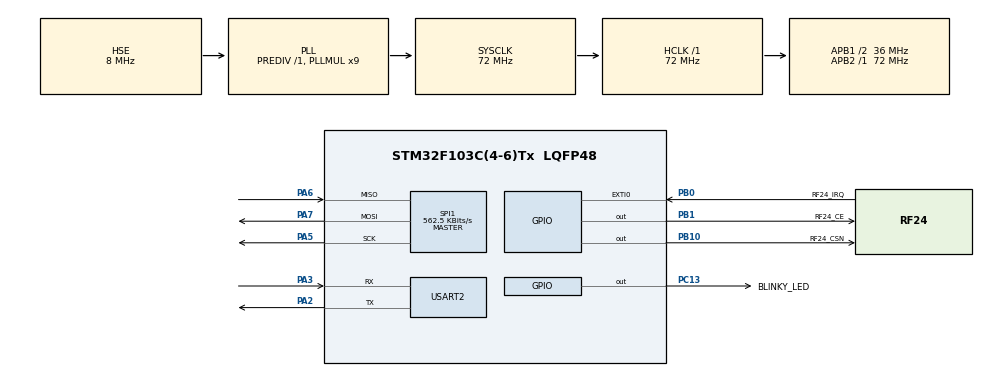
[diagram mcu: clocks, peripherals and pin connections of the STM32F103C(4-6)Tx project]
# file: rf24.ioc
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ADC1.Channel-0\#ChannelRegularConversion=ADC_CHANNEL_TEMPSENSOR
ADC1.NbrOfConversionFlag=1
ADC1.Rank-0\#ChannelRegularConversion=1
ADC1.SamplingTime-0\#ChannelRegularConversion=ADC_SAMPLETIME_1CYCLE_5
ADC1.master=1
Mcu.Family=STM32F1
Mcu.Name=STM32F103C(4-6)Tx
Mcu.Package=LQFP48
NVIC.PriorityGroup=NVIC_PRIORITYGROUP_4
PA2.Mode=Asynchronous
PA2.Signal=USART2_TX
PA3.Mode=Asynchronous
PA3.Signal=USART2_RX
PA5.Mode=Full_Duplex_Master
PA5.Signal=SPI1_SCK
PA6.Mode=Full_Duplex_Master
PA6.Signal=SPI1_MISO
PA7.Mode=Full_Duplex_Master
PA7.Signal=SPI1_MOSI
PB0.GPIO_Label=RF24_IRQ
PB0.GPIO_PuPd=GPIO_PULLUP
PB0.Signal=GPXTI0
PB1.GPIO_Label=RF24_CE
PB1.GPIO_PuPd=GPIO_PULLUP
PB1.GPIO_Speed=GPIO_SPEED_FREQ_HIGH
PB1.Signal=GPIO_Output
PB10.GPIO_Label=RF24_CSN
PB10.GPIO_PuPd=GPIO_PULLUP
PB10.GPIO_Speed=GPIO_SPEED_FREQ_HIGH
PB10.PinState=GPIO_PIN_RESET
PB10.Signal=GPIO_Output
PC13-TAMPER-RTC.GPIO_Label=BLINKY_LED
PC13-TAMPER-RTC.Signal=GPIO_Output
PD0-OSC_IN.Mode=HSE-External-Oscillator
PD0-OSC_IN.Signal=RCC_OSC_IN
PD1-OSC_OUT.Mode=HSE-External-Oscillator
PD1-OSC_OUT.Signal=RCC_OSC_OUT
ProjectManager.HeapSize=0x300
ProjectManager.StackSize=0x300
ProjectManager.TargetToolchain=SW4STM32
RCC.ADCPresc=RCC_ADCPCLK2_DIV6
RCC.AHBFreq_Value=72000000
RCC.APB1CLKDivider=RCC_HCLK_DIV2
RCC.APB1Freq_Value=36000000
RCC.APB1TimFreq_Value=72000000
RCC.APB2Freq_Value=72000000
RCC.APB2TimFreq_Value=72000000
RCC.HCLKFreq_Value=72000000
RCC.PLLMUL=RCC_PLL_MUL9
RCC.PLLSourceVirtual=RCC_PLLSOURCE_HSE
RCC.SYSCLKFreq_VALUE=72000000
RCC.SYSCLKSource=RCC_SYSCLKSOURCE_PLLCLK
RCC.USBFreq_Value=48000000
RCC.USBPrescaler=RCC_USBCLKSOURCE_PLL_DIV1_5
SPI1.BaudRatePrescaler=SPI_BAUDRATEPRESCALER_128
SPI1.CLKPolarity=SPI_POLARITY_LOW
SPI1.CalculateBaudRate=562.5 KBits/s
SPI1.DataSize=SPI_DATASIZE_8BIT
SPI1.Direction=SPI_DIRECTION_2LINES
SPI1.FirstBit=SPI_FIRSTBIT_MSB
SPI1.Mode=SPI_MODE_MASTER
SPI1.VirtualType=VM_MASTER
TIM1.AutoReloadPreload=TIM_AUTORELOAD_PRELOAD_ENABLE
TIM1.Period=18000
TIM1.Prescaler=65535
USART2.VirtualMode=VM_ASYNC
VP_ADC1_TempSens_Input.Mode=IN-TempSens
VP_SYS_VS_ND.Mode=No_Debug
VP_TIM1_VS_ClockSourceINT.Mode=Internal
VP_TIM1_VS_OPM.Mode=OPM_bit
board=custom

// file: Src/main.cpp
/* USER CODE BEGIN Header */
/**
 ******************************************************************************
 * @file           : main.c
 * @brief          : Main program body
 ******************************************************************************
 * @attention
 *
 * <h2><center>&copy; Copyright (c) 2020 STMicroelectronics.
 * All rights reserved.</center></h2>
 *
 * This software component is licensed by ST under BSD 3-Clause license,
 * the "License"; You may not use this file except in compliance with the
 * License. You may obtain a copy of the License at:
 *                        opensource.org/licenses/BSD-3-Clause
 *
 ******************************************************************************
 */
/* USER CODE END Header */

#include "main.h"

#include "DataTypes.h"
//#include "RF24.h"
#include "Nrf24.h"
#include "STM32Syscalls.h"
#include "Mesh.h"
#include "DebugSingleton.h"
#include "STM32Debug.h"
//#include <stdlib.h>

SPI_HandleTypeDef hspi1;
TIM_HandleTypeDef htim1;
UART_HandleTypeDef huart2;
ADC_HandleTypeDef hadc1;

void SystemClock_Config(void);
static void MX_GPIO_Init(void);
static void MX_SPI1_Init(void);
static void MX_TIM1_Init(void);
static void MX_USART2_UART_Init(void);
static void MX_ADC1_Init(void);

/* USER CODE BEGIN PFP */
/* USER CODE BEGIN PFP */

/* USER CODE END PFP */

//gpio::GPIOInterface *mesh_gpio;
syscalls::SyscallsInterface *mesh_syscalls;
//spi::SPIInterface *mesh_spi;
//network::RF24 *radio;
debugger::DebugInterface *debug;
mesh::Mesh *meshNetwork;
network::NetworkInterface *nwInterface;

bool server = false;

/****************** User Config ***************************/
/***      Set this radio as radio number 0 or 1         ***/
bool radioNumber = 0;

/* Hardware configuration: Set up nRF24L01 radio on SPI bus plus pins 7 & 8 */
/**********************************************************/

uint8_t addresses[][6] = {"1Node","2Node"};

// Used to control whether this node is sending or receiving
bool role = radioNumber;

int main(void)
{

	/* MCU Configuration--------------------------------------------------------*/

	/* Reset of all peripherals, Initializes the Flash interface and the Systick. */
	HAL_Init();

	/* Configure the system clock */
	SystemClock_Config();

	/* Initialize all configured peripherals */
	MX_GPIO_Init();
	MX_SPI1_Init();
	MX_TIM1_Init();
	MX_USART2_UART_Init();
	MX_ADC1_Init();

	mesh_syscalls = new syscalls::STM32Syscalls(&htim1, &hadc1, &hspi1, &huart2);
	debugger::DebugSingleton::createSTM32Instance(mesh_syscalls);
	debug = debugger::DebugSingleton::getInstance();

	debug->info("%s", "SYSTEM INIT DONE");

//	test::log_debug((char*)"s", "s");
//	log_debug("sss", "sss", 1);
//	log_debug((char*)"%s", "TEST");
//
//	int rsp_time = 0;
//	if(rsp_time){
//		rsp_time = 2;
//	}
//

	debug->info("%s", "MESH INIT STARTING");

	struct syscalls::gpio_pins pins;
	pins.ce_port = RF24_CE_GPIO_Port;
	pins.ce_pin = RF24_CE_Pin;
	pins.csn_port = RF24_CSN_GPIO_Port;
	pins.csn_pin = RF24_CSN_Pin;

//	mesh_spi = new spi::SPIStm32f103(&hspi1);
	//
//	mesh_gpio = new gpio::GPIOStm32f103();
	mesh_syscalls->gpio_init_pins(&pins);
//	mesh_gpio->init_pins(&pins);
	//
	mesh_syscalls->set_cpu_speed(syscalls::SPEED_72MHZ);
	mesh_syscalls->init();

	debug->info("%s", "MESH INIT DONE");

	debug->info("%s", "RADIO INIT STARTING");
//	radio = new network::RF24(mesh_gpio, mesh_syscalls, mesh_spi);
//	radio->begin();

	// Set the PA Level low to prevent power supply related issues since this is a
	// getting_started sketch, and the likelihood of close proximity of the devices. RF24_PA_MAX is default.
//	radio->setPALevel(network::RF24_PA_LOW);

	// Open a writing and reading pipe on each radio, with opposite addresses
//	if(radioNumber){
//		radio->openWritingPipe(addresses[1]);
//		radio->openReadingPipe(1,addresses[0]);
//	}else{
//		radio->openWritingPipe(addresses[0]);
//		radio->openReadingPipe(1,addresses[1]);
//	}
//
//	// Start the radio listening for data
//	radio->startListening();
//
//
//	while(!radio->isChipConnected())
//	{
//		HAL_Delay(1);
//	}
//

	nwInterface = new network::Nrf24(mesh_syscalls);
	meshNetwork = new mesh::Mesh(nwInterface,mesh_syscalls);

	debug->info("%s", "RADIO INIT DONE");

	char MSG[5];
	syscalls::SyscallsInterface::copy_data(MSG, "HEJ", 3);

	struct net_address address;
	syscalls::SyscallsInterface::mem_clr(&address, sizeof(address));
//	nethelper::NetHelper::generate_temporary_address(&address);

	/* Make sure to test the randomizer */

	debug->info("%s", "STARTING MAIN");

	if(server) {
		debug->info("%s", "STARTING SERVER");
		meshNetwork->setMaster();
	}

	while (1)
	{

		/* Doing mesh */
		meshNetwork->run();
		mesh_syscalls->msleep(200);
		if(server)
			debug->info("%s", "Running master");
		else
			debug->info("%s", "Running client");
//		HAL_Delay(1000);
//		HAL_GPIO_TogglePin(BLINKY_LED_GPIO_Port, BLINKY_LED_Pin);
//		char inten[10];

//		if(role)
//			debug->debug("%s", "STARTING CLIENT");
//		else
//			debug->debug("%s", "STARTING SERVER");
//
//
//
//
//		/****************** Ping Out Role ***************************/
//		if (role == 1)  {
//			debug->debug("%s", "PING OUT");
//
//			radio->stopListening();                                    // First, stop listening so we can talk.
//
//
//			debug->debug("%s", "Now sending.");
//
//			unsigned long start_time = 123;                             // Take the time, and send it.  This will block until complete
//			copy_data(MSG, "SEND", sizeof(MSG));
////			if (!radio->write( &start_time, sizeof(unsigned long) )){
//			if (!radio->write(MSG, sizeof(MSG))){
//				debug->debug("%s", "failed.");
//			}
//
//			radio->startListening();                                    // Now, continue listening
//
//			unsigned long started_waiting_at = 0;               // Set up a timeout period, get the current microseconds
//			bool timeout = false;                                   // Set up a variable to indicate if a response was received or not
//
//			while ( ! radio->available() ){                             // While nothing is received
//				if (started_waiting_at > 2000 ){            // If waited longer than 200ms, indicate timeout and exit while loop
//					timeout = true;
//					break;
//				}
//				started_waiting_at++;
//				HAL_Delay(1);
//			}
//
//			if ( timeout ){                                             // Describe the results
//				debug->debug("%s", "Failed, response timed out.");
//			}else{
//				unsigned long got_time;                                 // Grab the response, compare, and send to debugging spew
////				radio->read( &got_time, sizeof(unsigned long) );
//				radio->read(MSG, sizeof(MSG) );
//				unsigned long end_time = 456;
//				int printme = (int)got_time;
//
//				debug->debug("%s %s", "HERE: ", MSG);
//
//				// Spew it
////				Serial.print(F("Sent "));
////				Serial.print(start_time);
////				Serial.print(F(", Got response "));
////				Serial.print(got_time);
////				Serial.print(F(", Round-trip delay "));
////				Serial.print(end_time-start_time);
////				Serial.println(F(" microseconds"));
//			}
//
//			// Try again 1s later
//		}
//		HAL_Delay(1000);
//
//
//
//		/****************** Pong Back Role ***************************/
//
//		if ( role == 0 )
//		{
//			debug->debug("%s", "PONG BACK");
//			unsigned long got_time;
//
//			if( radio->available()){
//				// Variable for the received timestamp
//				while (radio->available()) {                                   // While there is data ready
////					radio->read( &got_time, sizeof(unsigned long) );             // Get the payload
//					radio->read( MSG, sizeof(MSG) );             // Get the payload
//					HAL_Delay(1);
//				}
//
//				debug->debug("Got msg: %s", MSG);
//				copy_data(MSG, "RETR", sizeof(MSG));
//				radio->stopListening();                                        // First, stop listening so we can talk
//				radio->write(MSG, sizeof(MSG) );              // Send the final one back.
////				radio->write( &got_time, sizeof(unsigned long) );              // Send the final one back.
//				radio->startListening();                                       // Now, resume listening so we catch the next packets.
//				debug->debug("%s", "Sent response ");
//				debug->debug("Got time: %d", got_time);
////				Serial.print(F("Sent response "));
////				Serial.println(got_time);
//			}
//		}

	}
	/* USER CODE END 3 */
}

void SystemClock_Config(void)
{
  RCC_OscInitTypeDef RCC_OscInitStruct = {0};
  RCC_ClkInitTypeDef RCC_ClkInitStruct = {0};

  /** Initializes the CPU, AHB and APB busses clocks
  */
  RCC_OscInitStruct.OscillatorType = RCC_OSCILLATORTYPE_HSE;
  RCC_OscInitStruct.HSEState = RCC_HSE_ON;
  RCC_OscInitStruct.HSEPredivValue = RCC_HSE_PREDIV_DIV1;
  RCC_OscInitStruct.HSIState = RCC_HSI_ON;
  RCC_OscInitStruct.PLL.PLLState = RCC_PLL_ON;
  RCC_OscInitStruct.PLL.PLLSource = RCC_PLLSOURCE_HSE;
  RCC_OscInitStruct.PLL.PLLMUL = RCC_PLL_MUL9;
  if (HAL_RCC_OscConfig(&RCC_OscInitStruct) != HAL_OK)
  {
    Error_Handler();
  }
  /** Initializes the CPU, AHB and APB busses clocks
  */
  RCC_ClkInitStruct.ClockType = RCC_CLOCKTYPE_HCLK|RCC_CLOCKTYPE_SYSCLK
                              |RCC_CLOCKTYPE_PCLK1|RCC_CLOCKTYPE_PCLK2;
  RCC_ClkInitStruct.SYSCLKSource = RCC_SYSCLKSOURCE_PLLCLK;
  RCC_ClkInitStruct.AHBCLKDivider = RCC_SYSCLK_DIV1;
  RCC_ClkInitStruct.APB1CLKDivider = RCC_HCLK_DIV2;
  RCC_ClkInitStruct.APB2CLKDivider = RCC_HCLK_DIV1;

  if (HAL_RCC_ClockConfig(&RCC_ClkInitStruct, FLASH_LATENCY_2) != HAL_OK)
  {
    Error_Handler();
  }
}

static void MX_SPI1_Init(void)
{

  /* SPI1 parameter configuration*/
  hspi1.Instance = SPI1;
  hspi1.Init.Mode = SPI_MODE_MASTER;
  hspi1.Init.Direction = SPI_DIRECTION_2LINES;
  hspi1.Init.DataSize = SPI_DATASIZE_8BIT;
  hspi1.Init.CLKPolarity = SPI_POLARITY_LOW;
  hspi1.Init.CLKPhase = SPI_PHASE_1EDGE;
  hspi1.Init.NSS = SPI_NSS_SOFT;
  hspi1.Init.BaudRatePrescaler = SPI_BAUDRATEPRESCALER_128;
  hspi1.Init.FirstBit = SPI_FIRSTBIT_MSB;
  hspi1.Init.TIMode = SPI_TIMODE_DISABLE;
  hspi1.Init.CRCCalculation = SPI_CRCCALCULATION_DISABLE;
  hspi1.Init.CRCPolynomial = 10;
  if (HAL_SPI_Init(&hspi1) != HAL_OK)
  {
    Error_Handler();
  }

}

static void MX_TIM1_Init(void)
{

  TIM_ClockConfigTypeDef sClockSourceConfig = {0};
  TIM_MasterConfigTypeDef sMasterConfig = {0};

  htim1.Instance = TIM1;
  htim1.Init.Prescaler = 65535;
  htim1.Init.CounterMode = TIM_COUNTERMODE_UP;
  htim1.Init.Period = 18000;
  htim1.Init.ClockDivision = TIM_CLOCKDIVISION_DIV1;
  htim1.Init.RepetitionCounter = 0;
  htim1.Init.AutoReloadPreload = TIM_AUTORELOAD_PRELOAD_ENABLE;
  if (HAL_TIM_Base_Init(&htim1) != HAL_OK)
  {
    Error_Handler();
  }
  sClockSourceConfig.ClockSource = TIM_CLOCKSOURCE_INTERNAL;
  if (HAL_TIM_ConfigClockSource(&htim1, &sClockSourceConfig) != HAL_OK)
  {
    Error_Handler();
  }
  if (HAL_TIM_OnePulse_Init(&htim1, TIM_OPMODE_SINGLE) != HAL_OK)
  {
    Error_Handler();
  }
  sMasterConfig.MasterOutputTrigger = TIM_TRGO_RESET;
  sMasterConfig.MasterSlaveMode = TIM_MASTERSLAVEMODE_DISABLE;
  if (HAL_TIMEx_MasterConfigSynchronization(&htim1, &sMasterConfig) != HAL_OK)
  {
    Error_Handler();
  }

}

static void MX_USART2_UART_Init(void)
{

  huart2.Instance = USART2;
  huart2.Init.BaudRate = 115200;
  huart2.Init.WordLength = UART_WORDLENGTH_8B;
  huart2.Init.StopBits = UART_STOPBITS_1;
  huart2.Init.Parity = UART_PARITY_NONE;
  huart2.Init.Mode = UART_MODE_TX_RX;
  huart2.Init.HwFlowCtl = UART_HWCONTROL_NONE;
  huart2.Init.OverSampling = UART_OVERSAMPLING_16;
  if (HAL_UART_Init(&huart2) != HAL_OK)
  {
    Error_Handler();
  }

}

static void MX_GPIO_Init(void)
{
  GPIO_InitTypeDef GPIO_InitStruct = {0};

  /* GPIO Ports Clock Enable */
  __HAL_RCC_GPIOC_CLK_ENABLE();
  __HAL_RCC_GPIOD_CLK_ENABLE();
  __HAL_RCC_GPIOA_CLK_ENABLE();
  __HAL_RCC_GPIOB_CLK_ENABLE();

  /*Configure GPIO pin Output Level */
  HAL_GPIO_WritePin(BLINKY_LED_GPIO_Port, BLINKY_LED_Pin, GPIO_PIN_RESET);

  /*Configure GPIO pin Output Level */
  HAL_GPIO_WritePin(GPIOB, RF24_CE_Pin|RF24_CSN_Pin, GPIO_PIN_RESET);

  /*Configure GPIO pin : BLINKY_LED_Pin */
  GPIO_InitStruct.Pin = BLINKY_LED_Pin;
  GPIO_InitStruct.Mode = GPIO_MODE_OUTPUT_PP;
  GPIO_InitStruct.Pull = GPIO_NOPULL;
  GPIO_InitStruct.Speed = GPIO_SPEED_FREQ_LOW;
  HAL_GPIO_Init(BLINKY_LED_GPIO_Port, &GPIO_InitStruct);

  /*Configure GPIO pin : RF24_IRQ_Pin */
  GPIO_InitStruct.Pin = RF24_IRQ_Pin;
  GPIO_InitStruct.Mode = GPIO_MODE_IT_RISING;
  GPIO_InitStruct.Pull = GPIO_PULLUP;
  HAL_GPIO_Init(RF24_IRQ_GPIO_Port, &GPIO_InitStruct);

  /*Configure GPIO pins : RF24_CE_Pin RF24_CSN_Pin */
  GPIO_InitStruct.Pin = RF24_CE_Pin|RF24_CSN_Pin;
  GPIO_InitStruct.Mode = GPIO_MODE_OUTPUT_PP;
  GPIO_InitStruct.Pull = GPIO_PULLUP;
  GPIO_InitStruct.Speed = GPIO_SPEED_FREQ_HIGH;
  HAL_GPIO_Init(GPIOB, &GPIO_InitStruct);

}

static void MX_ADC1_Init(void)
{

	ADC_ChannelConfTypeDef sConfig = {0};

	/** Common config
	 */

	  hadc1.Instance = ADC1;
	  hadc1.Init.ScanConvMode = ADC_SCAN_DISABLE;
	  hadc1.Init.ContinuousConvMode = DISABLE;
	  hadc1.Init.DiscontinuousConvMode = DISABLE;
	  hadc1.Init.ExternalTrigConv = ADC_SOFTWARE_START;
	  hadc1.Init.DataAlign = ADC_DATAALIGN_RIGHT;
	  hadc1.Init.NbrOfConversion = 1;
	  if (HAL_ADC_Init(&hadc1) != HAL_OK)
	  {
	    Error_Handler();
	  }
	  /** Configure Regular Channel
	  */
	  sConfig.Channel = ADC_CHANNEL_TEMPSENSOR;
	  sConfig.Rank = ADC_REGULAR_RANK_1;
	  sConfig.SamplingTime = ADC_SAMPLETIME_1CYCLE_5;
	  if (HAL_ADC_ConfigChannel(&hadc1, &sConfig) != HAL_OK)
	  {
	    Error_Handler();
	  }

}

void HAL_GPIO_EXTI_Callback(uint16_t GPIO_Pin){
	debug->debug("%s, %s, %d", __FILE__, __FUNCTION__, __LINE__);
	if(GPIO_Pin == RF24_IRQ_Pin){
		debug->debug("%s, %s, %d", __FILE__, __FUNCTION__, __LINE__);
		nwInterface->irq();
	}
}

void Error_Handler(void)
{
}

/************************ (C) COPYRIGHT STMicroelectronics *****END OF FILE****/
